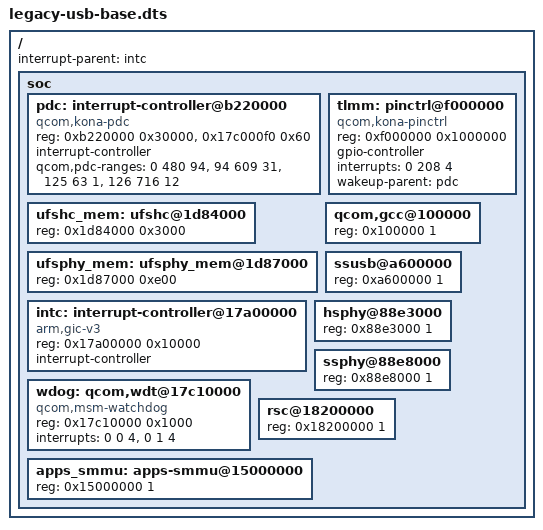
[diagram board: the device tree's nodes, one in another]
// SPDX-License-Identifier: GPL-2.0-only
// Synthetic overlay targets only. Contains no handset data.
/dts-v1/;
/ {
    #address-cells = <1>;
    #size-cells = <1>;
    interrupt-parent = <&intc>;
    soc {
        #address-cells = <1>;
        #size-cells = <1>;
        ranges;
        pdc: interrupt-controller@b220000 {
            compatible = "qcom,kona-pdc";
            reg = <0xb220000 0x30000>, <0x17c000f0 0x60>;
            interrupt-controller;
            #interrupt-cells = <2>;
            qcom,pdc-ranges = <0 480 94>, <94 609 31>, <125 63 1>, <126 716 12>;
        };
        tlmm: pinctrl@f000000 {
            compatible = "qcom,kona-pinctrl";
            reg = <0xf000000 0x1000000>;
            gpio-controller;
            #gpio-cells = <2>;
            interrupts = <0 208 4>;
            wakeup-parent = <&pdc>;
        };
        ufshc_mem: ufshc@1d84000 { reg = <0x1d84000 0x3000>; };
        ufsphy_mem: ufsphy_mem@1d87000 { reg = <0x1d87000 0xe00>; };
        intc: interrupt-controller@17a00000 {
            compatible = "arm,gic-v3";
            reg = <0x17a00000 0x10000>;
            #interrupt-cells = <3>;
            #address-cells = <0>;
            interrupt-controller;
        };
        wdog: qcom,wdt@17c10000 {
            compatible = "qcom,msm-watchdog";
            reg = <0x17c10000 0x1000>;
            interrupts = <0 0 4>, <0 1 4>;
        };
        qcom,gcc@100000 { reg = <0x100000 1>; };
        ssusb@a600000 { reg = <0xa600000 1>; };
        hsphy@88e3000 { reg = <0x88e3000 1>; };
        ssphy@88e8000 { reg = <0x88e8000 1>; };
        rsc@18200000 { reg = <0x18200000 1>; };
        apps_smmu: apps-smmu@15000000 {
            reg = <0x15000000 1>;
            #iommu-cells = <2>;
        };
    };
};
